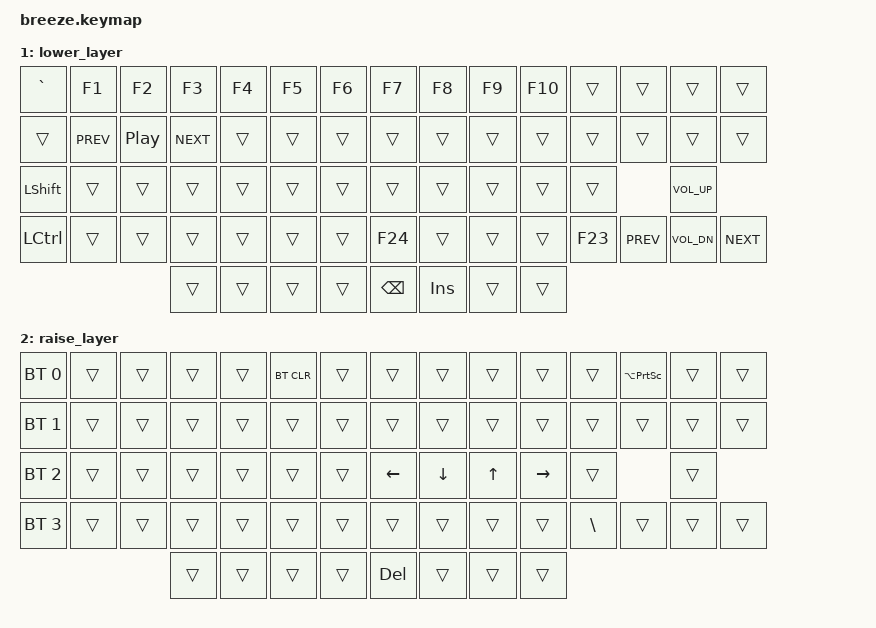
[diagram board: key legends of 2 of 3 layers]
/*
 * Copyright (c) 2022 The ZMK Contributors
 *
 * SPDX-License-Identifier: MIT
 */

#include <behaviors.dtsi>
#include <dt-bindings/zmk/bt.h>
#include <dt-bindings/zmk/keys.h>

/ {
    keymap {
        compatible = "zmk,keymap";

        default_layer {
            // Ref: https://zmkfirmware.dev/docs/codes/
            // ----------------------------------------------------------------------------------------------------------------------------------
            // |  ESC  |  1  |  2  |  3   |  4   |  5   |                   |  6   |  7    |  8    |  9   |   0   | | |  \  | -/_  | =/+ |
            // |  TAB  |  Q  |  W  |  E   |  R   |  T   |                   |  Y   |  U    |  I    |  O   |   P   |  \   | |  [  |  ]   | RBKT |
            // | CAPS  |  A  |  S  |  D   |  F   |  G   |                   |  H   |  J    |  K    |  L   |   ;   |  '   | |     |  UP  |      |
            // | LCTRL |  Z  |  X  |  C   |  V   |  B   |                   |  N   |  M    |  ,    |  .   |   /   | Mute | |  L  |  DN  |  R   |
            //                     | LALT | GUI  | ALT  | SPACE |   | ENTER | BSPC | RAISE | LOWER |

            bindings = <
  &kp ESC  &kp N1  &kp N2    &kp N3    &kp N4      &kp N5                        &kp N6  &kp N7     &kp N8   &kp N9    &kp N0        &kp GRAVE  &kp BSLH  &kp MINUS  &kp EQUAL
  &kp TAB   &kp Q   &kp W     &kp E     &kp R       &kp T                         &kp Y   &kp U      &kp I    &kp O     &kp P         &kp BSPC   &kp DEL   &kp LBKT   &kp RBKT
&kp LSHFT   &kp A   &kp S     &kp D     &kp F       &kp G                         &kp H   &kp J      &kp K    &kp L  &kp SEMI         &kp APOS               &kp UP
&kp LCTRL   &kp Z   &kp X     &kp C     &kp V       &kp B                         &kp N   &kp M  &kp COMMA  &kp DOT  &kp FSLH  &kp PRINTSCREEN  &kp LEFT   &kp DOWN  &kp RIGHT
                           &kp LALT  &kp LGUI  &mo 1 LALT  &kp SPACE  &kp BSPC  &kp RET   &mo 2  &kp RCTRL
            >;
        };

        lower_layer {
            // ---------------------------------------------------------------------------------------------------------------------------------- 
            // | GRAVE |  F1 |  F2 |  F3  |  F4  |  F5  |                   |  F6  |  F7  |  F8  |  F9  | F10  |       | | HOME  |      |      | 
            // |      |     |  ↑  |      |      |      |                   |      |      |      |      |       |       | |  END  | Mute | Play | 
            // | CAPS |  ←  |  ↓  |  →   |      |      |                   |      |      |      |      |       |       | |       | Vol+ |      | 
            // | SHIFT |     |     |      |      |      |                   |      |      |      |      |       |       | | Prev  | Vol- | Next | 
            //                    |      |      |      |        |  |  BSPC | INS  |      |      |

            bindings = <
&kp GRAVE      &kp F1            &kp F2      &kp F3  &kp F4  &kp F5                     &kp F6   &kp F7  &kp F8  &kp F9  &kp F10   &trans      &trans        &trans      &trans
   &trans  &kp C_PREV  &kp C_PLAY_PAUSE  &kp C_NEXT  &trans  &trans                     &trans   &trans  &trans  &trans   &trans   &trans      &trans        &trans      &trans
&kp LSHFT      &trans            &trans      &trans  &trans  &trans                     &trans   &trans  &trans  &trans   &trans   &trans              &kp C_VOL_UP
&kp LCTRL      &trans            &trans      &trans  &trans  &trans                     &trans  &kp F24  &trans  &trans   &trans  &kp F23  &kp C_PREV  &kp C_VOL_DN  &kp C_NEXT
                                             &trans  &trans  &trans  &trans  &kp BSPC  &kp INS   &trans  &trans
            >;
        };

        raise_layer {
            // ---------------------------------------------------------------------------------------------------------------------------------- 
            // | BT1 |     |     |      |      | BT_CLR |                   |      |       |       |      |       |       | | LA PSCRN |      |      | 
            // | BT2 |     |     |      |      |        |                   |      |       |       |      |       |       | |     |      |      | 
            // | BT3 |     |     |      |      |        |                   |      |   <-  |   ↓   |  ↑   |  →   |       | |     |      |      | 
            // | BT4 |     |     |      |      |        |                   |      |       |       |      |       |   \   | |     |      |      | 
            //                   |      |      |        |        |  |  DEL  |      |       |       |

            bindings = <
&bt BT_SEL 0  &trans  &trans  &trans  &trans  &bt BT_CLR                   &trans    &trans    &trans  &trans     &trans    &trans  &kp LA(PSCRN)  &trans  &trans
&bt BT_SEL 1  &trans  &trans  &trans  &trans      &trans                   &trans    &trans    &trans  &trans     &trans    &trans         &trans  &trans  &trans
&bt BT_SEL 2  &trans  &trans  &trans  &trans      &trans                   &trans  &kp LEFT  &kp DOWN  &kp UP  &kp RIGHT    &trans                 &trans
&bt BT_SEL 3  &trans  &trans  &trans  &trans      &trans                   &trans    &trans    &trans  &trans     &trans  &kp BSLH         &trans  &trans  &trans
                              &trans  &trans      &trans  &trans  &kp DEL  &trans    &trans    &trans
            >;
        };
    };
};
